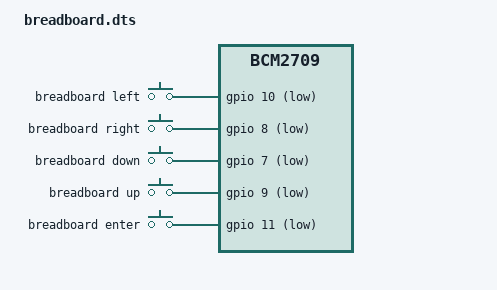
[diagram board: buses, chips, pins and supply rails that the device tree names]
    /dts-v1/;
    /plugin/;
    / {
       compatible = "brcm,bcm2835", "brcm,bcm2708", "brcm,bcm2709";
       
       fragment@0 {
          target-path = "/";
          __overlay__ {
             keypad: breadboard_keys {
                compatible = "gpio-keys";
                #address-cells = <1>;
                #size-cells = <0>;
		autorepeat;
                button@10 {
                   label = "breadboard left";
                   linux,code = <105>;
                   gpios = <&gpio 10 1>;
                };
                button@8 {
                   label = "breadboard right";
                   linux,code = <106>;
                   gpios = <&gpio 8 1>;
                };
                button@7 {
                   label = "breadboard down";
                   linux,code = <108>;
                   gpios = <&gpio 7 1>;
                };
                button@9 {
                   label = "breadboard up";
                   linux,code = <103>;
                   gpios = <&gpio 9 1>;
                };
                button@11 {
                   label = "breadboard enter";
                   linux,code = <14>;
                   gpios = <&gpio 11 1>;
                };
             };
          };
       };
    };
